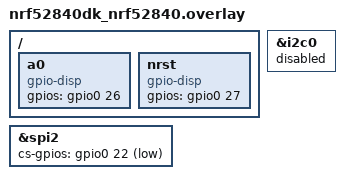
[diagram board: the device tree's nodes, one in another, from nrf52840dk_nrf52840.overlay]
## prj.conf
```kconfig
# nothing here
CONFIG_GPIO=y
CONFIG_SPI=y
```

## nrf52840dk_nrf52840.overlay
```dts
// To get started, press Ctrl+Space to bring up the completion menu and view the available nodes.

// You can also use the buttons in the sidebar to perform actions on nodes.
// Actions currently available include:

// * Enabling / disabling the node
// * Adding the bus to a bus
// * Removing the node
// * Connecting ADC channels

// For more help, browse the DeviceTree documentation at https://docs.zephyrproject.org/latest/guides/dts/index.html
// You can also visit the nRF DeviceTree extension documentation at https://nrfconnect.github.io/vscode-nrf-connect/devicetree/nrfdevicetree.html

&spi2 {
    status = "okay";
    cs-gpios = < &gpio0 22 GPIO_ACTIVE_LOW >;
    // nhd: nhd@0 {
    //     compatible = "nordic,nrf-spi";
    //     reg = <0>;
    //     spi-max-frequency = <1600000>;
    // };
};

&i2c0 {
    status = "disabled";
};

/ {
    a0: a0 {
        compatible = "gpio-disp";
        gpios = <&gpio0 26 GPIO_ACTIVE_HIGH>; 
    };
};

/ {
    nrst: nrst {
        compatible = "gpio-disp";
        gpios = <&gpio0 27 GPIO_ACTIVE_HIGH>; 
    };
};
```

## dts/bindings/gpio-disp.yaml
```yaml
description: GPIO parent node

compatible: "gpio-disp"

properties:
  gpios:
    type: phandle-array
    required: true
    description: |
      The selection pins connected to the display.
```

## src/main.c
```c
/*
 * Copyright (c) 2012-2014 Wind River Systems, Inc.
 *
 * SPDX-License-Identifier: Apache-2.0
 */

#include <zephyr/kernel.h>
#include <zephyr/drivers/gpio.h>
#include <zephyr/drivers/spi.h>

static const struct gpio_dt_spec rs_pin = GPIO_DT_SPEC_GET_OR(DT_NODELABEL(a0), gpios, {0});
static const struct gpio_dt_spec reset_pin = GPIO_DT_SPEC_GET_OR(DT_NODELABEL(nrst), gpios, {0});

void st7565_comm(struct device *spi, const struct spi_config *spi_cfg, unsigned char data) {
	gpio_pin_set_dt(&rs_pin, 0);
	const struct spi_buf_set tx = {
		.buffers = &(const struct spi_buf){
			.buf = &data,
			.len = 1,
		},
		.count = 1,
	};
	spi_write(spi, spi_cfg, &tx);
}

void main(void)
{
	printk("Program start: %s\n", CONFIG_BOARD);

	gpio_pin_configure_dt(&rs_pin, GPIO_OUTPUT_INACTIVE);
	gpio_pin_configure_dt(&reset_pin, GPIO_OUTPUT_INACTIVE);

	struct spi_config spi_cfg = {};
	struct device *spi = DEVICE_DT_GET(DT_NODELABEL(spi2));
	spi_cfg.operation = SPI_WORD_SET(8) | SPI_TRANSFER_MSB | SPI_OP_MODE_MASTER; // TODO half-duplex
	spi_cfg.frequency = 1000000U;
	printk("SPI init complete\n");

	// first display reset
	gpio_pin_set_dt(&reset_pin, 0);
	k_msleep(100);
	gpio_pin_set_dt(&reset_pin, 1);
	k_msleep(100);
	printk("GPIO init complete\n");

	// init
	st7565_comm(spi, &spi_cfg, 0xA0);
	st7565_comm(spi, &spi_cfg, 0xAE);
	st7565_comm(spi, &spi_cfg, 0xC0);
	st7565_comm(spi, &spi_cfg, 0xA2);
	st7565_comm(spi, &spi_cfg, 0x2F);
	st7565_comm(spi, &spi_cfg, 0x26);
	st7565_comm(spi, &spi_cfg, 0x81);
	st7565_comm(spi, &spi_cfg, 0x11);
	st7565_comm(spi, &spi_cfg, 0xAF);
	printk("Disp config complete\n");




}
```
